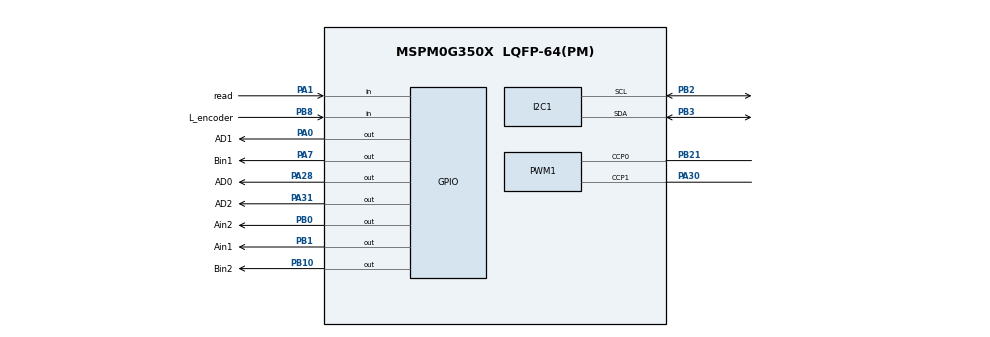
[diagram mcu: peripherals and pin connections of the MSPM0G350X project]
/**
 * @cliArgs --device "MSPM0G350X" --part "Default" --package "LQFP-64(PM)" --product "mspm0_sdk@2.10.00.04"
 * @versions {"tool":"1.26.2+4477"}
 */

/**
 * Import the modules used in this configuration.
 */
const GPIO   = scripting.addModule("/ti/driverlib/GPIO", {}, false);
const GPIO1  = GPIO.addInstance();
const GPIO2  = GPIO.addInstance();
const GPIO3  = GPIO.addInstance();
const GPIO4  = GPIO.addInstance();
const GPIO5  = GPIO.addInstance();
const GPIO6  = GPIO.addInstance();
const GPIO7  = GPIO.addInstance();
const I2C    = scripting.addModule("/ti/driverlib/I2C", {}, false);
const I2C1   = I2C.addInstance();
const PWM    = scripting.addModule("/ti/driverlib/PWM", {}, false);
const PWM1   = PWM.addInstance();
const SYSCTL = scripting.addModule("/ti/driverlib/SYSCTL");
const TIMER  = scripting.addModule("/ti/driverlib/TIMER", {}, false);
const TIMER1 = TIMER.addInstance();
const TIMER2 = TIMER.addInstance();
const UART   = scripting.addModule("/ti/driverlib/UART", {}, false);
const UART1  = UART.addInstance();

/**
 * Write custom configuration values to the imported modules.
 */
GPIO1.$name                         = "MotorLCtl";
GPIO1.associatedPins.create(2);
GPIO1.associatedPins[0].$name       = "Bin1";
GPIO1.associatedPins[0].pin.$assign = "PA7";
GPIO1.associatedPins[1].$name       = "Bin2";
GPIO1.associatedPins[1].pin.$assign = "PB10";

const Board = scripting.addModule("/ti/driverlib/Board", {}, false);

GPIO2.$name                         = "MotorRCtl";
GPIO2.associatedPins.create(2);
GPIO2.associatedPins[0].$name       = "Ain1";
GPIO2.associatedPins[0].pin.$assign = "PB1";
GPIO2.associatedPins[1].$name       = "Ain2";
GPIO2.associatedPins[1].pin.$assign = "PB0";

GPIO3.$name                         = "Gray";
GPIO3.port                          = "PORTA";
GPIO3.associatedPins.create(3);
GPIO3.associatedPins[0].$name       = "AD0";
GPIO3.associatedPins[0].pin.$assign = "PA28";
GPIO3.associatedPins[1].$name       = "AD1";
GPIO3.associatedPins[1].pin.$assign = "PA0";
GPIO3.associatedPins[2].$name       = "AD2";
GPIO3.associatedPins[2].pin.$assign = "PA31";

GPIO4.$name                         = "Grayread";
GPIO4.port                          = "PORTA";
GPIO4.associatedPins[0].$name       = "read";
GPIO4.associatedPins[0].direction   = "INPUT";
GPIO4.associatedPins[0].pin.$assign = "PA1";

GPIO5.$name                              = "KEY1";
GPIO5.port                               = "PORTB";
GPIO5.associatedPins[0].direction        = "INPUT";
GPIO5.associatedPins[0].$name            = "PIN_23";
GPIO5.associatedPins[0].assignedPin      = "23";
GPIO5.associatedPins[0].internalResistor = "PULL_UP";

GPIO6.$name                              = "KEY2";
GPIO6.port                               = "PORTB";
GPIO6.associatedPins[0].$name            = "PIN_26";
GPIO6.associatedPins[0].direction        = "INPUT";
GPIO6.associatedPins[0].assignedPin      = "26";
GPIO6.associatedPins[0].internalResistor = "PULL_DOWN";

GPIO7.$name                                 = "Encoder";
GPIO7.associatedPins.create(2);
GPIO7.associatedPins[0].$name               = "L_encoder";
GPIO7.associatedPins[0].direction           = "INPUT";
GPIO7.associatedPins[0].assignedPort        = "PORTB";
GPIO7.associatedPins[0].assignedPin         = "8";
GPIO7.associatedPins[0].assignedPortSegment = "Lower";
GPIO7.associatedPins[0].polarity            = "RISE_FALL";
GPIO7.associatedPins[0].interruptEn         = true;
GPIO7.associatedPins[0].pin.$assign         = "PB8";
GPIO7.associatedPins[1].$name               = "R_encoder";
GPIO7.associatedPins[1].direction           = "INPUT";
GPIO7.associatedPins[1].assignedPort        = "PORTA";
GPIO7.associatedPins[1].assignedPortSegment = "Upper";
GPIO7.associatedPins[1].assignedPin         = "17";
GPIO7.associatedPins[1].interruptEn         = true;
GPIO7.associatedPins[1].polarity            = "RISE_FALL";

I2C1.$name                             = "I2C_OLED";
I2C1.basicEnableController             = true;
I2C1.basicControllerStandardBusSpeed   = "Fast";
I2C1.peripheral.$assign                = "I2C1";
I2C1.peripheral.sdaPin.$assign         = "PB3";
I2C1.peripheral.sclPin.$assign         = "PB2";
I2C1.sdaPinConfig.hideOutputInversion  = scripting.forceWrite(false);
I2C1.sdaPinConfig.onlyInternalResistor = scripting.forceWrite(false);
I2C1.sdaPinConfig.passedPeripheralType = scripting.forceWrite("Digital");
I2C1.sdaPinConfig.$name                = "ti_driverlib_gpio_GPIOPinGeneric6";
I2C1.sclPinConfig.hideOutputInversion  = scripting.forceWrite(false);
I2C1.sclPinConfig.onlyInternalResistor = scripting.forceWrite(false);
I2C1.sclPinConfig.passedPeripheralType = scripting.forceWrite("Digital");
I2C1.sclPinConfig.$name                = "ti_driverlib_gpio_GPIOPinGeneric7";

PWM1.timerCount                         = 1600;
PWM1.timerStartTimer                    = true;
PWM1.pwmMode                            = "EDGE_ALIGN_UP";
PWM1.$name                              = "Motor";
PWM1.peripheral.$assign                 = "TIMG8";
PWM1.peripheral.ccp0Pin.$assign         = "PB21";
PWM1.peripheral.ccp1Pin.$assign         = "PA30";
PWM1.PWM_CHANNEL_0.$name                = "ti_driverlib_pwm_PWMTimerCC0";
PWM1.PWM_CHANNEL_1.$name                = "ti_driverlib_pwm_PWMTimerCC1";
PWM1.ccp0PinConfig.direction            = scripting.forceWrite("OUTPUT");
PWM1.ccp0PinConfig.hideOutputInversion  = scripting.forceWrite(false);
PWM1.ccp0PinConfig.onlyInternalResistor = scripting.forceWrite(false);
PWM1.ccp0PinConfig.passedPeripheralType = scripting.forceWrite("Digital");
PWM1.ccp0PinConfig.$name                = "ti_driverlib_gpio_GPIOPinGeneric0";
PWM1.ccp1PinConfig.direction            = scripting.forceWrite("OUTPUT");
PWM1.ccp1PinConfig.hideOutputInversion  = scripting.forceWrite(false);
PWM1.ccp1PinConfig.onlyInternalResistor = scripting.forceWrite(false);
PWM1.ccp1PinConfig.passedPeripheralType = scripting.forceWrite("Digital");
PWM1.ccp1PinConfig.$name                = "ti_driverlib_gpio_GPIOPinGeneric1";

SYSCTL.forceDefaultClkConfig = true;

TIMER1.interrupts         = ["ZERO"];
TIMER1.timerMode          = "PERIODIC";
TIMER1.$name              = "LMotor";
TIMER1.timerClkDiv        = 4;
TIMER1.peripheral.$assign = "TIMG7";

TIMER2.timerMode          = "PERIODIC";
TIMER2.interrupts         = ["ZERO"];
TIMER2.$name              = "RMotor";
TIMER2.timerClkDiv        = 4;
TIMER2.peripheral.$assign = "TIMG6";

UART1.$name             = "UART_0";
UART1.targetBaudRate    = 115200;
UART1.txPinConfig.$name = "ti_driverlib_gpio_GPIOPinGeneric2";
UART1.rxPinConfig.$name = "ti_driverlib_gpio_GPIOPinGeneric3";

/**
 * Pinmux solution for unlocked pins/peripherals. This ensures that minor changes to the automatic solver in a future
 * version of the tool will not impact the pinmux you originally saw.  These lines can be completely deleted in order to
 * re-solve from scratch.
 */
Board.peripheral.$suggestSolution            = "DEBUGSS";
Board.peripheral.swclkPin.$suggestSolution   = "PA20";
Board.peripheral.swdioPin.$suggestSolution   = "PA19";
GPIO5.associatedPins[0].pin.$suggestSolution = "PB23";
GPIO6.associatedPins[0].pin.$suggestSolution = "PB26";
GPIO7.associatedPins[1].pin.$suggestSolution = "PA17";
SYSCTL.peripheral.$suggestSolution           = "SYSCTL";
UART1.peripheral.$suggestSolution            = "UART0";
UART1.peripheral.rxPin.$suggestSolution      = "PA11";
UART1.peripheral.txPin.$suggestSolution      = "PA10";
